# GD32A72_A74x register map
File version: 1.0
CPU: CM7 r2p1, little endian, MPU, FPU, DSP, 4 interrupt priority bits
Registers are 32-bit, read-write, reset 0x0 unless marked. A register's access mark holds for its fields unless they carry their own. Offsets are from the block's base; [hi:lo] are bit positions; {n}, {i} and the like mark numbered series; 'fields as' and 'values as' point back to an identical list.

## ENET_MAC
Base 0x4000A000
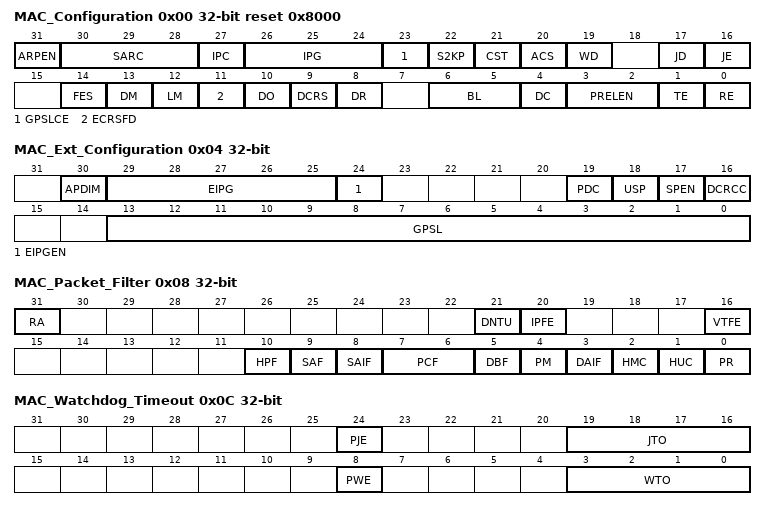
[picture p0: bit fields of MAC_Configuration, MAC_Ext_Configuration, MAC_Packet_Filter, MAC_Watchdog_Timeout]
0x00 MAC_Configuration reset 0x8000
  [31] ARPEN — ARP Offload Enable
  [30:28] SARC — Source Address Insertion Or Replacement Control
    0=SA_CTRL_IN (mti_sa_ctrl_i and ati_sa_ctrl_i input signals control the SA field generation); 2=MAC0_INS_SA (Contents of are inserted in the SA field); 3=MAC0_REP_SA (Contents of replace the SA field); 6=MAC1_INS_SA (Contents of are inserted in the SA field); 7=MAC1_REP_SA (Contents of replace the SA field)
  [27] IPC — Checksum Offload
    0=DISABLE (Disabled); 1=ENABLE (Enabled)
  [26:24] IPG — Inter-Packet Gap
    0=96-bit times IPG; 1=88-bit times IPG; 2=80-bit times IPG; 3=72-bit times IPG; 4=64-bit times IPG; 5=56-bit times IPG; 6=48-bit times IPG; 7=40-bit times IPG
  [23] GPSLCE — Giant Packet Size Limit Control Enable
    0=DISABLE (Disabled); 1=ENABLE (Enabled)
  [22] S2KP — IEEE 802.3 Support For 2K Packets
    0=DISABLE (Disabled); 1=ENABLE (Enabled)
  [21] CST — CRC Stripping For Type Packets
    0=DISABLE (Disabled); 1=ENABLE (Enabled)
  [20] ACS — Automatic Pad Or CRC Stripping
    0=DISABLE (Disabled); 1=ENABLE (Enabled)
  [19] WD — Watchdog Disable
    0=ENABLE (Enabled); 1=DISABLE (Disabled)
  [17] JD — Jabber Disable
    0=ENABLE (Enabled); 1=DISABLE (Disabled)
  [16] JE — Jumbo Packet Enable
    0=DISABLE (Disabled); 1=ENABLE (Enabled)
  [14] FES — Speed
    0=M_10_1000M (10 Mbit/s if PS = 1 and 1 Gbps if PS = 0); 1=M_100_2500M (100 Mbit/s if PS = 1 and 2.5 Gbps if PS = 0)
  [13] DM — Duplex Mode
    0=HDUPLX (Half-duplex mode); 1=FDUPLX (Full-duplex mode)
  [12] LM — Loopback Mode
    0=DISABLE (Disabled); 1=ENABLE (Enabled)
  [11] ECRSFD — Enable Carrier Sense In Full-Duplex Mode
    0=DISABLE (Disabled); 1=ENABLE (Enabled)
  [10] DO — Disable Receive Own
    0=ENABLE (Enabled); 1=DISABLE (Disabled)
  [9] DCRS — Disable Carrier Sense During Transmission
    0=ENABLE (Enabled); 1=DISABLE (Disabled)
  [8] DR — Disable Retry
    0=ENABLE (Enabled); 1=DISABLE (Disabled)
  [6:5] BL — Back-Off Limit
    0=MIN_N_10 (k = min(n,10)); 1=MIN_N_8 (k = min(n,8)); 2=MIN_N_4 (k = min(n,4)); 3=MIN_N_1 (k = min(n,1))
  [4] DC — Deferral Check
    0=DISABLE (Disabled); 1=ENABLE (Enabled)
  [3:2] PRELEN — Preamble Length for Transmit Packets
    0=M_7BYTES (7 bytes); 1=M_5BYTES (5 bytes); 2=M_3BYTES (3 bytes)
  [1] TE — Transmitter Enable
    0=DISABLE (Disabled); 1=ENABLE (Enabled)
  [0] RE — Receiver Enable
    0=DISABLE (Disabled); 1=ENABLE (Enabled)
0x04 MAC_Ext_Configuration — MAC Extended Configuration
  [30] APDIM — ARP Packet Drop if IP Address Mismatch
  [29:25] EIPG — Extended Inter-Packet Gap
  [24] EIPGEN — Extended Inter-Packet Gap Enable
    0=DISABLE (Disabled); 1=ENABLE (Enabled)
  [19] PDC — Packet Duplication Control
    0=DISABLE (Disabled); 1=ENABLE (Enabled)
  [18] USP — Unicast Slow Protocol Packet Detect
    0=DISABLE (Disabled); 1=ENABLE (Enabled)
  [17] SPEN — Slow Protocol Detection Enable
    0=DISABLE (Disabled); 1=ENABLE (Enabled)
  [16] DCRCC — Disable CRC Checking For Received Packets
    0=ENABLE (Enabled); 1=DISABLE (Disabled)
  [13:0] GPSL — Giant Packet Size Limit
0x08 MAC_Packet_Filter
  [31] RA — Receive All
    0=DISABLE (Receive All is disabled); 1=ENABLE (Receive All is enabled)
  [21] DNTU — Drop Non-TCP/UDP Over IP Packets
    0=FWD (Forwards); 1=DROP (Drops)
  [20] IPFE — Layer 3 and Layer 4 Filter Enable
    0=DISABLE (Disabled); 1=ENABLE (Enabled)
  [16] VTFE — VLAN Tag Filter Enable
    0=DISABLE (Disabled); 1=ENABLE (Enabled)
  [10] HPF — Hash Or Perfect Filter
    0=DISABLE (Disabled); 1=ENABLE (Enabled)
  [9] SAF — Source Address Filter Enable
    0=DISABLE (Disabled); 1=ENABLE (Enabled)
  [8] SAIF — SA Inverse Filtering
    0=DISABLE (Disabled); 1=ENABLE (Enabled)
  [7:6] PCF — Pass Control Packets
    0=FLTR_ALL (MAC filters all the control packets from reaching the application); 1=FW_XCPT_PAU (MAC forwards all the control packets, except pause packets, to the application even if they fail the address filter); 2=FW_ALL (MAC forwards all the control packets to the application even if they fail the address filter); 3=FW_PASS (MAC forwards all the control packets that pass the address filter)
  [5] DBF — Disable Broadcast Packets
    0=ENABLE (Enabled); 1=DISABLE (Disabled)
  [4] PM — Pass All Multicast
    0=DISABLE (Disabled); 1=ENABLE (Enabled)
  [3] DAIF — DA Inverse Filtering
    0=DISABLE (Disabled); 1=ENABLE (Enabled)
  [2] HMC — Hash Multicast
    0=DISABLE (Disabled); 1=ENABLE (Enabled)
  [1] HUC — Hash Unicast
    0=DISABLE (Disabled); 1=ENABLE (Enabled)
  [0] PR — Promiscuous Mode
    0=DISABLE (Disabled); 1=ENABLE (Enabled)
0x0C MAC_Watchdog_Timeout
  [24] PJE — Programmable Jabber Enable
  [19:16] JTO — Jabber Timeout
  [8] PWE — Programmable Watchdog Enable
    0=DISABLE (Disabled); 1=ENABLE (Enabled)
  [3:0] WTO — Watchdog Timeout
    {v}=M_{v+2}KBYTES ({v+2} KB) (v=0..13); 14=M_16383BYTES (16383 bytes)
0x10 MAC_Hash_Table_Reg0 — MAC Hash Table First 32 Bits
  [31:0] HT31T0
0x14 MAC_Hash_Table_Reg1 — MAC Hash Table Second 32 Bits
  [31:0] HT63T32
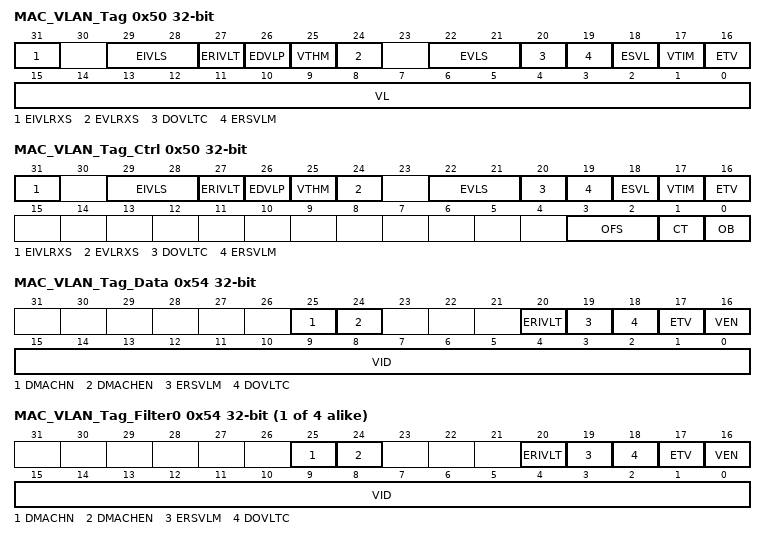
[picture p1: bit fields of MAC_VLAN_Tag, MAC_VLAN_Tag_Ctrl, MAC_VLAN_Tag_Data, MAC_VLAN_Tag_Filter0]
0x50 MAC_VLAN_Tag (MAC_VLAN view)
  [31] EIVLRXS — Enable Inner VLAN Tag In Receive Status
    0=DISABLE (Disabled); 1=ENABLE (Enabled)
  [29:28] EIVLS — Enable Inner VLAN Tag Stripping
    0=DONOT (Do not strip); 1=IFPASS (Strip if VLAN filter passes); 2=IFFAIL (Strip if VLAN filter fails); 3=ALWAYS (Always strip)
  [27] ERIVLT — Enable Inner VLAN Tag Comparison
    0=DISABLE (Disabled); 1=ENABLE (Enabled)
  [26] EDVLP — Enable Double VLAN Processing
    0=DISABLE (Disabled); 1=ENABLE (Enabled)
  [25] VTHM — VLAN Tag Hash Table Match
    0=DISABLE (Disabled); 1=ENABLE (Enabled)
  [24] EVLRXS — Enable VLAN Tag In Receive Status
    0=DISABLE (Disabled); 1=ENABLE (Enabled)
  [22:21] EVLS — Enable VLAN Tag Stripping
    values as EIVLS
  [20] DOVLTC — Disable VLAN Type Check
    0=ENABLE (Enabled); 1=DISABLE (Disabled)
  [19] ERSVLM — Enable Receive S-VLAN Match
    0=DISABLE (Disabled); 1=ENABLE (Enabled)
  [18] ESVL — Enable S-VLAN
    0=DISABLE (Disabled); 1=ENABLE (Enabled)
  [17] VTIM — VLAN Tag Inverse Match Enable
    0=DISABLE (Disabled); 1=ENABLE (Enabled)
  [16] ETV — Enable Tag For VLAN
    0=DISABLE (Disabled); 1=ENABLE (Enabled)
  [15:0] VL — VLAN Tag Identifier for Receive Packets
0x50 MAC_VLAN_Tag_Ctrl (MAC_VLAN view) — MAC VLAN Tag Control
  [31] EIVLRXS — Enable Inner VLAN Tag In Receive Status
    0=DISABLE (Disabled); 1=ENABLE (Enabled)
  [29:28] EIVLS — Enable Inner VLAN Tag Stripping
    values as MAC_VLAN_Tag.EIVLS
  [27] ERIVLT — Enable Inner VLAN Tag Comparison
    0=DISABLE (Disabled); 1=ENABLE (Enabled)
  [26] EDVLP — Enable Double VLAN Processing
    0=DISABLE (Disabled); 1=ENABLE (Enabled)
  [25] VTHM — VLAN Tag Hash Table Match
    0=DISABLE (Disabled); 1=ENABLE (Enabled)
  [24] EVLRXS — Enable VLAN Tag In Receive Status
    0=DISABLE (Disabled); 1=ENABLE (Enabled)
  [22:21] EVLS — Enable VLAN Tag Stripping
    values as MAC_VLAN_Tag.EIVLS
  [20] DOVLTC — Disable VLAN Type Check
    0=ENABLE (Enabled); 1=DISABLE (Disabled)
  [19] ERSVLM — Enable Receive S-VLAN Match
    0=DISABLE (Disabled); 1=ENABLE (Enabled)
  [18] ESVL — Enable S-VLAN
    0=DISABLE (Disabled); 1=ENABLE (Enabled)
  [17] VTIM — VLAN Tag Inverse Match Enable
    0=DISABLE (Disabled); 1=ENABLE (Enabled)
  [16] ETV — Enable Tag For VLAN
    0=DISABLE (Disabled); 1=ENABLE (Enabled)
  [3:2] OFS — Offset
  [1] CT — Command Type
    0=WRITE (Write operation); 1=READ (Read operation)
  [0] OB — Operation Busy
    0=DISABLE (Disabled); 1=ENABLE (Enabled)
0x54 MAC_VLAN_Tag_Data (MAC_VLAN_Tag view)
  [25] DMACHN — DMA Channel Number
  [24] DMACHEN — DMA Channel Number Enable
    0=DISABLE (Disabled); 1=ENABLE (Enabled)
  [20] ERIVLT — Enable Inner VLAN Tag
    0=DISABLE (Disabled); 1=ENABLE (Enabled)
  [19] ERSVLM — Enable S-VLAN Match
    0=DISABLE (Disabled); 1=ENABLE (Enabled)
  [18] DOVLTC — Disable VLAN Type Comparison
    0=ENABLE (Enabled); 1=DISABLE (Disabled)
  [17] ETV — VLAN Comparison
    0=M_16BIT (16-bit VLAN comparison); 1=M_12BIT (12-bit VLAN comparison)
  [16] VEN — VLAN Tag Enable
    0=DISABLE (Disabled); 1=ENABLE (Enabled)
  [15:0] VID — VLAN Tag ID
0x54 MAC_VLAN_Tag_Filter{i} (MAC_VLAN_Tag view) (i=0..3)
  fields as MAC_VLAN_Tag_Data
0x58 MAC_VLAN_Hash_Table
  [15:0] VLHT — VLAN Hash Table
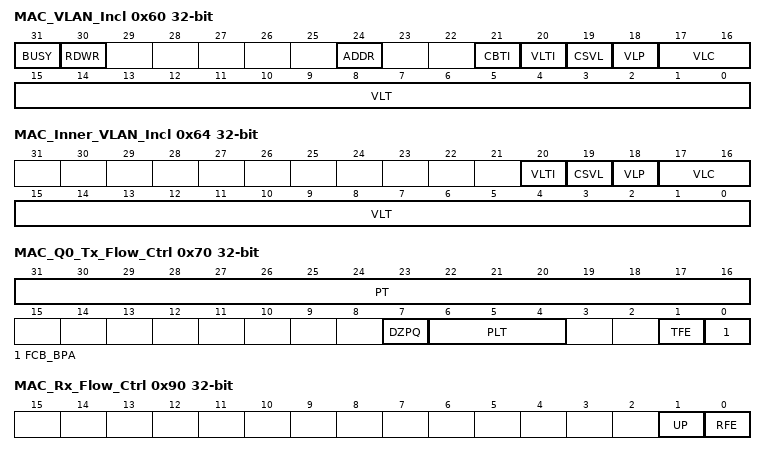
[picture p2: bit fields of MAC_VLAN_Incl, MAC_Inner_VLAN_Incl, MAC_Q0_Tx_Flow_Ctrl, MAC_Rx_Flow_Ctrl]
0x60 MAC_VLAN_Incl — MAC VLAN Inclusion Or Replacement
  [31] BUSY ro
    0=INACTIVE (Busy status not detected); 1=ACTIVE (Busy status detected)
  [30] RDWR — Read Write Control
    0=READ (Read operation of indirect access); 1=WRITE (Write operation of indirect access)
  [24] ADDR — Address
  [21] CBTI — Channel-Based Tag Insertion
    0=DISABLE (Disabled); 1=ENABLE (Enabled)
  [20] VLTI — VLAN Tag Input
    0=DISABLE (Disabled); 1=ENABLE (Enabled)
  [19] CSVL — C-VLAN Or S-VLAN
    0=CVLAN; 1=SVLAN
  [18] VLP — VLAN Priority Control
    0=DISABLE (Disabled); 1=ENABLE (Enabled)
  [17:16] VLC — VLAN Tag Control
    0=NONE (No VLAN tag deletion, insertion, or replacement); 1=DELETE (VLAN tag deletion); 2=INSERT (VLAN tag insertion); 3=REPLACE (VLAN tag replacement)
  [15:0] VLT — VLAN Tag For Transmit Packets
0x64 MAC_Inner_VLAN_Incl — Inner VLAN Tag Inclusion Or Replacement
  [20] VLTI — VLAN Tag Input
    0=DISABLE (Disabled); 1=ENABLE (Enabled)
  [19] CSVL — C-VLAN Or S-VLAN
    0=CVLAN (C-VLAN type (8100h)); 1=SVLAN (S-VLAN type (88A8h))
  [18] VLP — VLAN Priority Control
    0=DISABLE (Disabled); 1=ENABLE (Enabled)
  [17:16] VLC — VLAN Tag Control in Transmit Packets
    values as MAC_VLAN_Incl.VLC
  [15:0] VLT — VLAN Tag For Transmit Packets
0x70 MAC_Q0_Tx_Flow_Ctrl — MAC Q0 Tx Flow Control
  [31:16] PT — Pause Time
  [7] DZPQ — Disable Zero-Quanta Pause
    0=ENABLE (Enabled); 1=DISABLE (Disabled)
  [6:4] PLT — Pause Low Threshold
    0=PT4 (Pause time minus 4 slot times (PT is 4 slot times)); 1=PT28 (Pause time minus 28 slot times (PT is 28 slot times)); 2=PT36 (Pause time minus 36 slot times (PT is 36 slot times)); 3=PT144 (Pause time minus 144 slot times (PT is 144 slot times)); 4=PT256 (Pause time minus 256 slot times (PT is 256 slot times)); 5=PT512 (Pause time minus 512 slot times (PT is 512 slot times))
  [1] TFE — Transmit Flow Control Enable
    0=DISABLE (Disabled); 1=ENABLE (Enabled)
  [0] FCB_BPA — Flow Control Busy Or Backpressure Activate
    0=DISABLE (Flow control busy or backpressure activate is disabled); 1=ENABLE (Flow control busy or backpressure activate is enabled)
0x90 MAC_Rx_Flow_Ctrl — MAC Receive Flow Control
  [1] UP — Unicast Pause Packet Detect
    0=DISABLE (Disabled); 1=ENABLE (Enabled)
  [0] RFE — Receive Flow Control Enable
    0=DISABLE (Disabled); 1=ENABLE (Enabled)
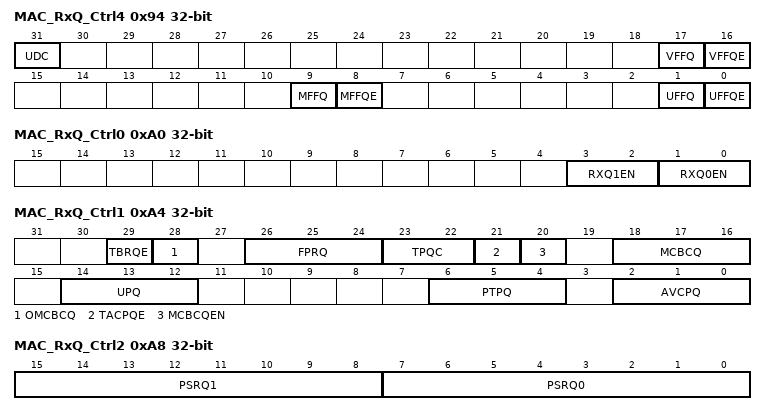
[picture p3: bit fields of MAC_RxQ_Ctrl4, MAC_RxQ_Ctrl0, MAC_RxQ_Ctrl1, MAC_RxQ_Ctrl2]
0x94 MAC_RxQ_Ctrl4 — MAC RxQ Control 4
  [31] UDC — Unicast Packet Duplication Control
  [17] VFFQ — VLAN Tag Filter Fail Packets Queue
  [16] VFFQE — VLAN Tag Filter Fail Packets Queuing Enable
    0=DISABLE (Disabled); 1=ENABLE (Enabled)
  [9] MFFQ — Multicast Address Filter Fail Packets Queue
  [8] MFFQE — Multicast Address Filter Fail Packets Queuing Enable
    0=DISABLE (Disabled); 1=ENABLE (Enabled)
  [1] UFFQ — Unicast Address Filter Fail Packets Queue
  [0] UFFQE — Unicast Address Filter Fail Packets Queuing Enable
    0=DISABLE (Disabled); 1=ENABLE (Enabled)
0xA0 MAC_RxQ_Ctrl0 — MAC RxQ Control 0
  [3:2] RXQ1EN — Receive Queue 1 Enable
    0=DISABLE (Queue not enabled); 1=EN_AV (Queue enabled for AV); 2=EN_DCB_GEN (Queue enabled for DCB/generic)
  [1:0] RXQ0EN — Receive Queue 0 Enable
    values as RXQ1EN
0xA4 MAC_RxQ_Ctrl1 — Receive Queue Control 1
  [29] TBRQE — Type Field Based Rx Queuing Enable
  [28] OMCBCQ — Over-riding MC-BC queue priority select
  [26:24] FPRQ — Frame Preemption Residue Queue
  [23:22] TPQC — Tagged PTP Over Ethernet Packets Queuing Control
  [21] TACPQE — Tagged AV Control Packets Queuing Enable
    0=DISABLE (Disabled); 1=ENABLE (Enabled)
  [20] MCBCQEN — Multicast And Broadcast Queue Enable
    0=DISABLE (Disabled); 1=ENABLE (Enabled)
  [18:16] MCBCQ — Multicast And Broadcast Queue
    {v}=QUEUE{v} (Receive queue {v}) (v=0..7)
  [14:12] UPQ — Untagged Packet Queue
    {v}=QUEUE{v} (Receive queue {v}) (v=0..7)
  [6:4] PTPQ — PTP Packets Queue
    {v}=QUEUE{v} (Receive queue {v}) (v=0..7)
  [2:0] AVCPQ — AV Untagged Control Packets Queue
    {v}=QUEUE{v} (Receive queue {v}) (v=0..7)
0xA8 MAC_RxQ_Ctrl2 — MAC RxQ Control 2
  [15:8] PSRQ1 — Priorities Selected In Receive Queue 1
  [7:0] PSRQ0 — Priorities Selected In Receive Queue 0
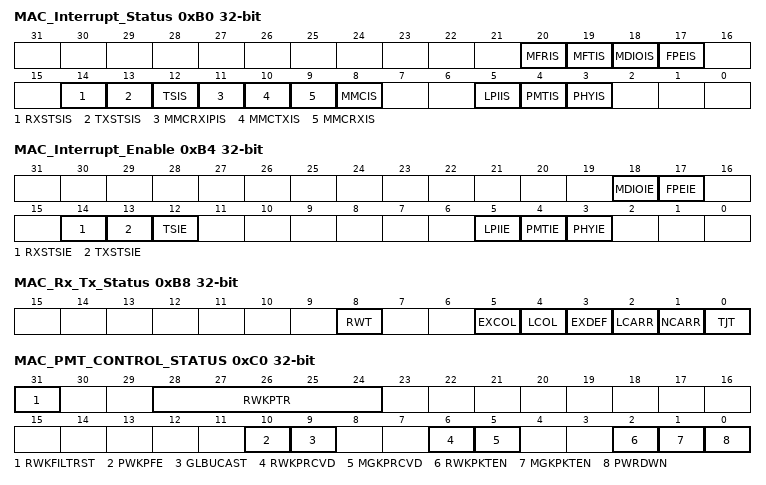
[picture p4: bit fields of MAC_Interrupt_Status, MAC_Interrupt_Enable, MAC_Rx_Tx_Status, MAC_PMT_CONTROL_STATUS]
0xB0 MAC_Interrupt_Status ro
  [20] MFRIS — MMC FPE Receive Interrupt Status
    0=INACTIVE; 1=ACTIVE
  [19] MFTIS — MMC FPE Transmit Interrupt Status
    0=INACTIVE; 1=ACTIVE
  [18] MDIOIS — MDIO Interrupt Status
    0=INACTIVE; 1=ACTIVE
  [17] FPEIS — Frame Preemption Interrupt Status
    0=INACTIVE; 1=ACTIVE (Ative)
  [14] RXSTSIS — Receive Status Interrupt
    0=INACTIVE; 1=ACTIVE
  [13] TXSTSIS — Transmit Status Interrupt
    0=INACTIVE; 1=ACTIVE
  [12] TSIS — Timestamp Interrupt Status
    0=INACTIVE; 1=ACTIVE
  [11] MMCRXIPIS — MMC Receive Checksum Offload Interrupt Status
  [10] MMCTXIS — MMC Transmit Interrupt Status
    0=INACTIVE; 1=ACTIVE
  [9] MMCRXIS — MMC Receive Interrupt Status
    0=INACTIVE; 1=ACTIVE
  [8] MMCIS — MMC Interrupt Status
    0=INACTIVE; 1=ACTIVE
  [5] LPIIS — LPI Interrupt Status
  [4] PMTIS — PMT Interrupt Status
  [3] PHYIS — PHY Interrupt
    0=INACTIVE (Not detected); 1=ACTIVE (Detected)
0xB4 MAC_Interrupt_Enable
  [18] MDIOIE — MDIO Interrupt Enable
    0=DISABLE (Disabled); 1=ENABLE (Enabled)
  [17] FPEIE — Frame Preemption Interrupt Enable
    0=DISABLE (Disabled); 1=ENABLE (Enabled)
  [14] RXSTSIE — Receive Status Interrupt Enable
    0=DISABLE (Disabled); 1=ENABLE (Enabled)
  [13] TXSTSIE — Transmit Status Interrupt Enable
    0=DISABLE (Disabled); 1=ENABLE (Enabled)
  [12] TSIE — Timestamp Interrupt Enable
    0=DISABLE (Disabled); 1=ENABLE (Enabled)
  [5] LPIIE — LPI Interrupt Enable
  [4] PMTIE — PMT Interrupt Enable
  [3] PHYIE — PHY Interrupt Enable
    0=DISABLE (Disabled); 1=ENABLE (Enabled)
0xB8 MAC_Rx_Tx_Status ro — MAC Rx Transmit Status
  [8] RWT — Receive Watchdog Timeout
    0=INACTIVE (No receive watchdog timed out); 1=ACTIVE (Receive watchdog timed out)
  [5] EXCOL — Excessive Collisions
    0=INACTIVE (No collision); 1=ACTIVE (Excessive collision is sensed)
  [4] LCOL — Late Collision
    0=INACTIVE (No collision); 1=ACTIVE (Late collision is sensed)
  [3] EXDEF — Excessive Deferral
    0=INACTIVE (No excessive deferral); 1=ACTIVE (Excessive deferral)
  [2] LCARR — Loss of Carrier
    0=INACTIVE (Carrier is present); 1=ACTIVE (Loss of carrier)
  [1] NCARR — No Carrier
    0=INACTIVE (Present); 1=ACTIVE (Absent)
  [0] TJT — Transmit Jabber Timeout
    0=INACTIVE (No transmit jabber timeout occurred); 1=ACTIVE (Transmit jabber timeout occurred)
0xC0 MAC_PMT_CONTROL_STATUS access per field — MAC PMT control and status register
  [31] RWKFILTRST rw — Remote Wake-Up Packet Filter Register Pointer Reset
  [28:24] RWKPTR ro — Remote Wake-up FIFO Pointer
  [10] PWKPFE rw — Remote Wake-up Packet Forwarding Enable
  [9] GLBUCAST rw — Global unicast bit
  [6] RWKPRCVD ro — Remote Wake-Up Packet Received
  [5] MGKPRCVD ro — Magic Packet Received
  [2] RWKPKTEN rw — Wakeup frame enable bit
  [1] MGKPKTEN rw — Magic Packet enable bit
  [0] PWRDWN rw — Power down bit
0xC4 MAC_RWK_Packet_Filter — MAC remote wakeup packet filter register
  [31:0] WKUPFRMFTR — RWK Packet Filter
0xC4 RWK_Filter0123_Byte_Mask (MAC_RWK_Packet_Filter view) — MAC remote wakeup packet filter0123 byte mask register
  [30:0] Filter0_Byte_Mask — Filter0 32-bit Mask
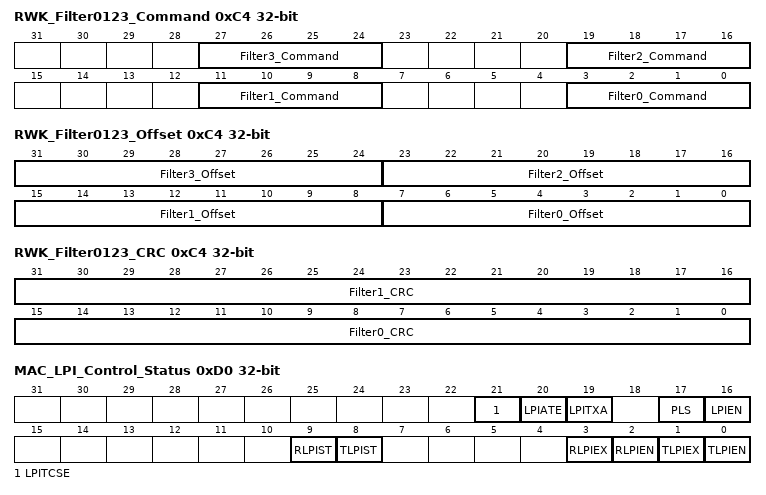
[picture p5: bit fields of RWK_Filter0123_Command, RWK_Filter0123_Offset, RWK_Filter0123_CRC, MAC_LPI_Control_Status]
0xC4 RWK_Filter0123_Command (MAC_RWK_Packet_Filter view) — MAC remote wakeup packet filter0123 command register
  [8n+3:8n] Filter{n}_Command (n=0..3)
0xC4 RWK_Filter0123_Offset (MAC_RWK_Packet_Filter view) — MAC remote wakeup packet filter0123 offset register
  [8n+7:8n] Filter{n}_Offset (n=0..3)
0xC4 RWK_Filter0123_CRC (MAC_RWK_Packet_Filter view) — MAC remote wakeup packet filter#i crc register
  [31:16] Filter1_CRC — Filter1 CRC-16
  [15:0] Filter0_CRC — Filter0 CRC-16
0xD0 MAC_LPI_Control_Status access per field — MAC LPI control and status register
  [21] LPITCSE rw — LPI Tx Clock Stop Enable
  [20] LPIATE rw — LPI Timer Enable
  [19] LPITXA rw — LPI Tx Automate
  [17] PLS rw — PHY Link Status
  [16] LPIEN rw — LPI Enable
  [9] RLPIST ro — Receive LPI State
  [8] TLPIST ro — Transmit LPI State
  [3] RLPIEX ro — Receive LPI Exit
  [2] RLPIEN ro — Receive LPI Entry
  [1] TLPIEX ro — Transmit LPI Exit
  [0] TLPIEN ro — Transmit LPI Entry
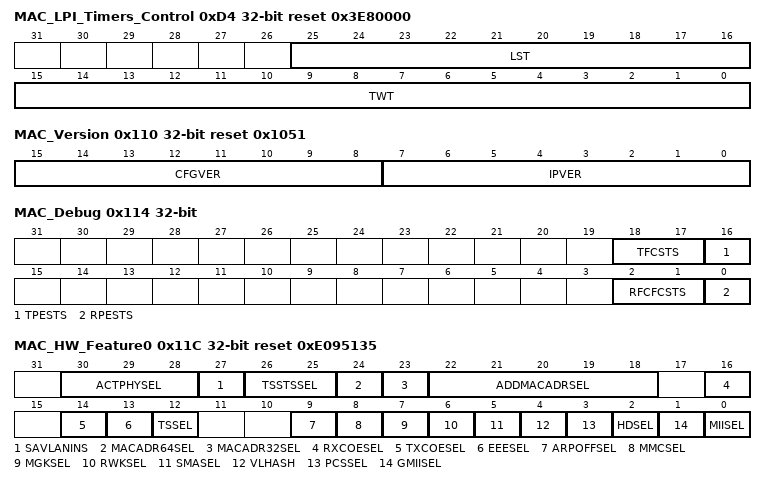
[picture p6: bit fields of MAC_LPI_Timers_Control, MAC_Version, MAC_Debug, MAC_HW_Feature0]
0xD4 MAC_LPI_Timers_Control reset 0x3E80000
  [25:16] LST — LPI LS Timer
  [15:0] TWT — LPI TW Timer
0xD8 MAC_LPI_Entry_Timer
  [19:3] LPIET — LPI Entry Timer
0xDC MAC_1US_Tic_Counter — MAC 1 microsecond tic counter register
  [11:0] TIC_1US_CNTR — 1US TIC Counter
0x110 MAC_Version ro reset 0x1051
  [15:8] CFGVER — IP Configuration Version
  [7:0] IPVER — IP Version
0x114 MAC_Debug ro
  [18:17] TFCSTS — MAC Transmit Packet Controller Status
    0=IDLE (Idle state); 1=WAITING (Waiting for one of these: status of the previous packet or IPG, or for the back-off period to be over); 2=GEN_TX_PAU (Generating and transmitting a pause control packet (in Full-Duplex mode)); 3=TRNSFR (Transferring input packet for transmission)
  [16] TPESTS — MAC GMII Or MII Transmit Protocol Engine Status
    0=INACTIVE (Not detected); 1=ACTIVE (Detected)
  [2:1] RFCFCSTS — MAC Receive Packet Controller FIFO Status
    0=INACTIVE; 1=ACTIVE
  [0] RPESTS — Receive Protocol Engine Status
    0=INACTIVE (Not detected); 1=ACTIVE (Detected)
0x11C MAC_HW_Feature0 ro reset 0xE095135 — MAC Hardware Feature 0
  [30:28] ACTPHYSEL — Active PHY Feature
    0=GMII_MII (GMII or MII); 1=RGMII; 2=SGMII; 3=TBI; 4=RMII; 5=RTBI; 6=SMII; 7=REVMIII
  [27] SAVLANINS — SA or VLAN Insertion Feature
    0=INACTIVE (Not selected); 1=ACTIVE (Selected)
  [26:25] TSSTSSEL — Timestamp System Time Source Feature
    0=INTRNL (Internal); 1=EXTRNL (External); 2=BOTH (Both internal and external)
  [24] MACADR64SEL — MAC Addresses 64-127
    0=INACTIVE (Not selected); 1=ACTIVE (Selected)
  [23] MACADR32SEL — MAC Addresses 32-63
    0=INACTIVE (Not selected); 1=ACTIVE (Selected)
  [22:18] ADDMACADRSEL — MAC Addresses 1-31
    0=INACTIVE (Not selected); 1=ACTIVE (Selected)
  [16] RXCOESEL — Receive Checksum Offload Feature
    0=INACTIVE (Not selected); 1=ACTIVE (Selected)
  [14] TXCOESEL — Transmit Checksum Offload Feature
    0=INACTIVE (Not selected); 1=ACTIVE (Selected)
  [13] EEESEL — Energy Efficient Ethernet (EEE) Feature
    0=INACTIVE (Not selected); 1=ACTIVE (Selected)
  [12] TSSEL — IEEE 1588-2008 Timestamp Feature
    0=INACTIVE (Not selected); 1=ACTIVE (Selected)
  [9] ARPOFFSEL — ARP Offload Feature
    0=INACTIVE (Not selected); 1=ACTIVE (Selected)
  [8] MMCSEL — MAC Management Counters (MMC) Feature
    0=INACTIVE (Not selected); 1=ACTIVE (Selected)
  [7] MGKSEL — PMT Magic Packet Feature
    0=INACTIVE (Not selected); 1=ACTIVE (Selected)
  [6] RWKSEL — PMT Remote Wake-Up Packet Feature
    0=INACTIVE (Not selected); 1=ACTIVE (Selected)
  [5] SMASEL — SMA (MDIO) Interface Feature
    0=INACTIVE (Not selected); 1=ACTIVE (Selected)
  [4] VLHASH — VLAN Hash Filter Feature
    0=INACTIVE (Not selected); 1=ACTIVE (Selected)
  [3] PCSSEL — PCS Select
    0=INACTIVE (No); 1=ACTIVE (Yes)
  [2] HDSEL — Half-Duplex Support Feature
    0=INACTIVE (Unavailable); 1=ACTIVE (Available)
  [1] GMIISEL — 1000 Mbit/s Support Feature
    0=INACTIVE (Unavailable); 1=ACTIVE (Available)
  [0] MIISEL — 10 or 100 Mbit/s Support Feature
    0=INACTIVE (Unavailable); 1=ACTIVE (Available)
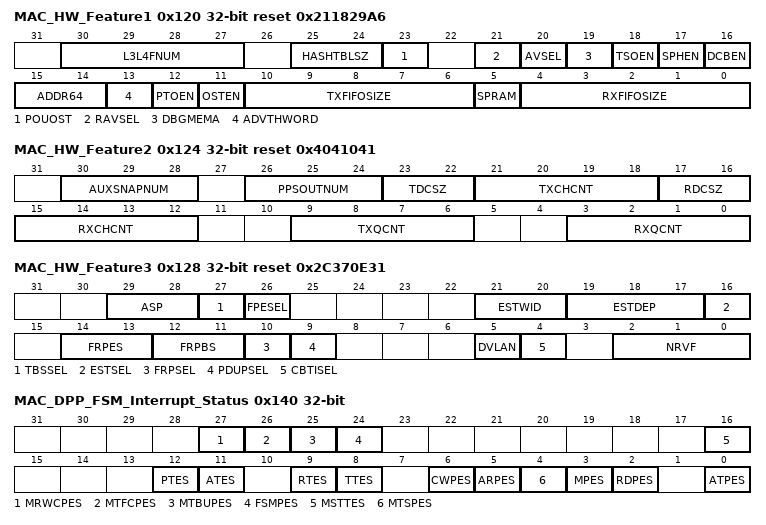
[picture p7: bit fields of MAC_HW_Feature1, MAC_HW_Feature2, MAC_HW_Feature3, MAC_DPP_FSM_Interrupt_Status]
0x120 MAC_HW_Feature1 ro reset 0x211829A6 — MAC Hardware Feature 1
  [30:27] L3L4FNUM — L3 Or L4 Filter Number
    0=NOFILT (No filters (0)); {v}=M_{v}FILT ({v}) (v=1..8)
  [25:24] HASHTBLSZ — Hash Table Size
    0=NO_HT (No hash table); 1=M_64 (64); 2=M_128 (128); 3=M_256 (256)
  [23] POUOST — One Step For PTP Over UDP/IP Feature
    0=INACTIVE (Not selected); 1=ACTIVE (Selected)
  [21] RAVSEL — Receive Side-Only AV Feature
    0=INACTIVE (Not selected); 1=ACTIVE (Selected)
  [20] AVSEL — AV Feature
    0=INACTIVE (Not selected); 1=ACTIVE (Selected)
  [19] DBGMEMA — DMA Debug Registers Enable Feature
    0=INACTIVE (Not selected); 1=ACTIVE (Selected)
  [18] TSOEN — TCP Segmentation Offload Enable Feature
    0=INACTIVE (Not selected); 1=ACTIVE (Selected)
  [17] SPHEN — Split Header Enable Feature
    0=INACTIVE (Not selected); 1=ACTIVE (Selected)
  [16] DCBEN — DCB Enable Feature
    0=INACTIVE (Not selected); 1=ACTIVE (Selected)
  [15:14] ADDR64 — Address Width Feature
    0=M_32 (32); 1=M_40 (40); 2=M_48 (48)
  [13] ADVTHWORD — IEEE 1588 High-Word Feature
    0=INACTIVE (Not selected); 1=ACTIVE (Selected)
  [12] PTOEN — PTP Offload Enable Feature
    0=INACTIVE (Not selected); 1=ACTIVE (Selected)
  [11] OSTEN — One-Step Timestamping Enable Feature
    0=INACTIVE (Not selected); 1=ACTIVE (Selected)
  [10:6] TXFIFOSIZE — MTL Transmit FIFO Size Feature
    0=M_128B (128 bytes); 1=M_256B (256 bytes); 2=M_512B (512 bytes); 3=M_1024B (1024 bytes); 4=M_2048B (2048 bytes); 5=M_4096B (4096 bytes); 6=M_8192B (8192 bytes); 7=M_16384B (16384 bytes); 8=M_32KB (32 KB); 9=M_64KB (64 KB); 10=M_128KB (128 KB)
  [5] SPRAM — Single Port RAM Feature
    0=INACTIVE (Not selected); 1=ACTIVE (Selected)
  [4:0] RXFIFOSIZE — MTL Receive FIFO Size Feature
    0=M_128B (128 bytes); 1=M_256B (256 bytes); 2=M_512B (512 bytes); 3=M_1024B (1024 bytes); 4=M_2048B (2048 bytes); 5=M_4096B (4096 bytes); 6=M_8192B (8192 bytes); 7=M_16384B (16384 bytes); 8=M_32KB (32 KB); 9=M_64KB (64 KB); 10=M_128KB (128 KB); 11=M_256KB (256 KB)
0x124 MAC_HW_Feature2 ro reset 0x4041041 — MAC Hardware Feature 2
  [30:28] AUXSNAPNUM — Number Of Auxiliary Snapshot Inputs
    0=NO_AUXI (No auxiliary input (0)); {v}=M_{v}_AUXI ({v}) (v=1..4)
  [26:24] PPSOUTNUM — Number Of PPS Outputs
    0=NO_PPSO (No PPS output (0)); {v}=M_{v}_PPSO ({v}) (v=1..4)
  [23:22] TDCSZ — Tx DMA Descriptor Cache Size in terms of 16-bytes descriptors
  [21:18] TXCHCNT — Number Of DMA Transmit Channels
    {v}=M_{v+1}TXCH ({v+1}) (v=0..7)
  [17:16] RDCSZ — Rx DMA Descriptor Cache Size in terms of 16-bytes descriptors
  [15:12] RXCHCNT — Number Of DMA Receive Channels
    {v}=M_{v+1}RXCH ({v+1}) (v=0..7)
  [9:6] TXQCNT — Number Of MTL Transmit Queues
    {v}=M_{v+1}TXQ ({v+1}) (v=0..7)
  [3:0] RXQCNT — Number Of MTL Receive Queues
    {v}=M_{v+1}RXQ ({v+1}) (v=0..7)
0x128 MAC_HW_Feature3 ro reset 0x2C370E31 — MAC Hardware Feature 3
  [29:28] ASP — Automotive Safety Package
    0=NONE (No safety features selected); 1=ECC_ONLY (Only "ECC protection for external memory" feature is selected); 2=AS_NPPE (All the safety features are selected without the "parity port enable for external interface" feature); 3=AS_PPE (All the safety features are selected with the "parity port enable for external interface" feature)
  [27] TBSSEL — Time-Based Scheduling Feature
    0=INACTIVE (Selected); 1=ACTIVE (Selected)
  [26] FPESEL — Frame Preemption Feature
    0=INACTIVE (Not selected); 1=ACTIVE (Selected)
  [21:20] ESTWID — Estimated Time Interval Width
    0=NOWIDTH (Width not configured); 1=WIDTH16 (16 bits); 2=WIDTH20 (20 bits); 3=WIDTH24 (24 bits)
  [19:17] ESTDEP — Depth Of Gate Control List
    0=NODEPTH (No depth configured); 1=DEPTH64 (64 bytes); 2=DEPTH128 (128 bytes); 3=DEPTH256 (256 bytes); 4=DEPTH512 (512 bytes); 5=DEPTH1024 (1024 bytes)
  [16] ESTSEL — Enhancements To Scheduling Traffic Feature
    0=INACTIVE (Not selected); 1=ACTIVE (Selected)
  [14:13] FRPES — Flexible Receive Parser Table Entry Size
    0=M_64ENTR (64); 1=M_128ENTR (128); 2=M_256ENTR (256)
  [12:11] FRPBS — Flexible Receive Parser Buffer Size
    0=M_64BYTES (64); 1=M_128BYTES (128); 2=M_256BYTES (256)
  [10] FRPSEL — Flexible Receive Parser Feature
    0=INACTIVE (Not selected); 1=ACTIVE (Selected)
  [9] PDUPSEL — Broadcast/Multicast Packet Duplication Feature
    0=INACTIVE (Not selected); 1=ACTIVE (Selected)
  [5] DVLAN — Double VLAN Tag Processing Feature
    0=INACTIVE (Not selected); 1=ACTIVE (Selected)
  [4] CBTISEL — Queue/Channel Based VLAN Tag Insertion On Transmit Feature
    0=INACTIVE (Not selected); 1=ACTIVE (Selected)
  [2:0] NRVF — Number Of Extended VLAN Tag Filters Indicates the number of selected extended VLAN tag filters.
    0=NO_ERVLAN (No filters (0)); 1=M_4_ERVLAN (4); 2=M_8_ERVLAN (8); 3=M_16_ERVLAN (16); 4=M_24_ERVLAN (24); 5=M_32_ERVLAN (32)
0x140 MAC_DPP_FSM_Interrupt_Status ro
  [27] MRWCPES — MTL RWC data path Parity Checker Error Status
  [26] MTFCPES — MAC TFC data path Parity Checker Error Status
  [25] MTBUPES — MAC TBU data path Parity Checker Error Status
  [24] FSMPES — FSM State Parity Error Status
    0=INACTIVE (Not detected); 1=ACTIVE (Detected)
  [16] MSTTES — Master Read Or Write Timeout Error Status
    0=INACTIVE (Not detected); 1=ACTIVE (Detected)
  [12] PTES — PTP FSM Timeout Error Status
    0=INACTIVE (Not detected); 1=ACTIVE (Detected)
  [11] ATES — APP FSM Timeout Error Status
    0=INACTIVE (Not detected); 1=ACTIVE (Detected)
  [9] RTES — Receive FSM Timeout Error Status
    0=INACTIVE (Not detected); 1=ACTIVE (Detected)
  [8] TTES — Transmit FSM Timeout Error Status
    0=INACTIVE (Not detected); 1=ACTIVE (Detected)
  [6] CWPES — CSR Write data path Parity Checker Error Status
  [5] ARPES — Application Receive Interface Data Path Parity Error Status
    0=INACTIVE (Not detected); 1=ACTIVE (Detected)
  [4] MTSPES — MTL Transmit Status Data Path Parity Checker Error Status
    0=INACTIVE (Not detected); 1=ACTIVE (Detected)
  [3] MPES — MTL Data Path Parity Checker Error Status
    0=INACTIVE (Not detected); 1=ACTIVE (Detected)
  [2] RDPES — Read Descriptor Parity Checker Error Status
    0=INACTIVE (Not detected); 1=ACTIVE (Detected)
  [0] ATPES — Application Transmit Interface Parity Checker Error Status
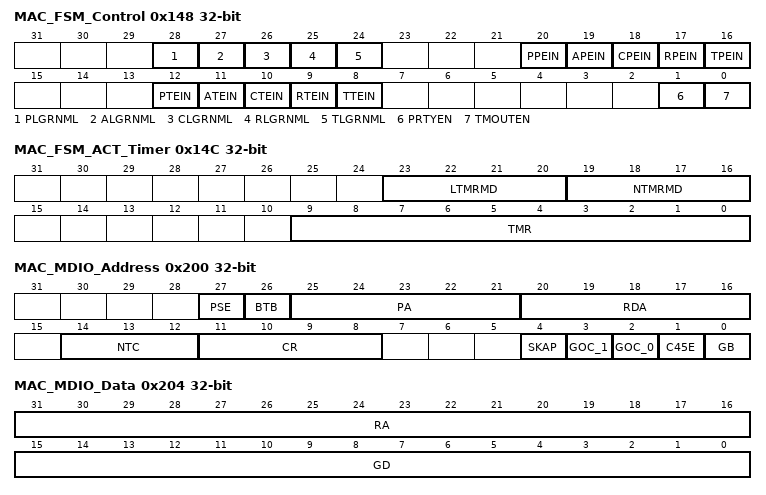
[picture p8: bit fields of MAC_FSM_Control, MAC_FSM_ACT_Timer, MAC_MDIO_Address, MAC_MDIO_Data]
0x148 MAC_FSM_Control
  [28] PLGRNML — PTP Large Or Normal Mode Select
    0=DISABLE (Normal mode); 1=ENABLE (Large mode)
  [27] ALGRNML — APP Large Or Normal Mode Select
    0=DISABLE (Normal mode); 1=ENABLE (Large mode)
  [26] CLGRNML — CSR Large/Normal Mode Select
    0=DISABLE (Normal mode); 1=ENABLE (Large mode)
  [25] RLGRNML — Receive Large Or Normal Mode Select
    0=DISABLE (Normal mode); 1=ENABLE (Large mode)
  [24] TLGRNML — Transmit Large Or Normal Mode Select
    0=DISABLE (Normal mode); 1=ENABLE (Large mode)
  [20] PPEIN — PTP FSM Parity Error Injection
    0=DISABLE (Disabled); 1=ENABLE (Enabled)
  [19] APEIN — APP FSM Parity Error Injection
    0=DISABLE (Disabled); 1=ENABLE (Enabled)
  [18] CPEIN — CSR FSM One Hot Protection Error Injection
    0=DISABLE (Disabled); 1=ENABLE (Enabled)
  [17] RPEIN — Receive FSM Parity Error Injection
    0=DISABLE (Disabled); 1=ENABLE (Enabled)
  [16] TPEIN — Transmit FSM Parity Error Injection
    0=DISABLE (Disabled); 1=ENABLE (Enabled)
  [12] PTEIN — PTP FSM Timeout Error Injection
    0=DISABLE (Disabled); 1=ENABLE (Enabled)
  [11] ATEIN — APP FSM Timeout Error Injection
    0=DISABLE (Disabled); 1=ENABLE (Enabled)
  [10] CTEIN — CSR FSM Timeout Error Injection
    0=DISABLE (Disabled); 1=ENABLE (Enabled)
  [9] RTEIN — Receive FSM Timeout Error Injection
    0=DISABLE (Disabled); 1=ENABLE (Enabled)
  [8] TTEIN — Transmit FSM Timeout Error Injection
    0=DISABLE (Disabled); 1=ENABLE (Enabled)
  [1] PRTYEN — Parity Enable
    0=DISABLE (Disabled); 1=ENABLE (Enabled)
  [0] TMOUTEN — Time Out Enable
    0=DISABLE (Disabled); 1=ENABLE (Enabled)
0x14C MAC_FSM_ACT_Timer
  [23:20] LTMRMD — Large Mode Timeout Value
    0=DISABLE (Timer disabled); 1=M_1MICRO_SEC (1 us); 2=M_4MILLI_SEC (1.024 ms (~4 ms)); 3=M_16MILLI_SEC (16.384 ms (~16 ms)); 4=M_64MILLI_SEC (65.536 ms (~64 ms)); 5=M_256MILLI_SEC (262.144 ms (~256 ms)); 6=M_1SEC (1.048 sec (~1 sec)); 7=M_4SEC (4.194 sec (~4sec)); 8=M_16SEC (16.777 sec (~16 sec)); 9=M_32SEC (33.554 sec (~32 sec)); 10=M_64SEC (67.108 sec (~64 sec))
  [19:16] NTMRMD — Normal Mode Timeout Value
    0=DISABLE (Timer disabled); 1=M_1MICRO_SEC (1 us); 2=M_4MILLI_SEC (1.024 ms (~4 ms)); 3=M_16MILLI_SEC (16.384 ms (~16 ms)); 4=M_64MILLI_SEC (65.536 ms (~64 ms)); 5=M_256MILLI_SEC (262.144 ms (~256 ms)); 6=M_1SEC (1.048 sec (~1 sec)); 7=M_4SEC (4.194 sec (~4 sec)); 8=M_16SEC (16.777 sec (~16 sec)); 9=M_32SEC (33.554 sec (~32 sec)); 10=M_64SEC (67.108 sec (~64 sec))
  [9:0] TMR — CSR Clocks For 1 us Tic
0x200 MAC_MDIO_Address
  [27] PSE — Preamble Suppression Enable
    0=DISABLE (Disabled); 1=ENABLE (Enabled)
  [26] BTB — Back-To-Back Transactions
    0=DISABLE (Disabled); 1=ENABLE (Enabled)
  [25:21] PA — Physical Layer Address
  [20:16] RDA — Register Or Device Address
  [14:12] NTC — Number Of Trailing Clocks
  [11:8] CR — CSR Clock Range
  [4] SKAP — Skip Address Packet
    0=DISABLE (Disabled); 1=ENABLE (Enabled)
  [3] GOC_1 — GMII Operation Command 1
    0=DISABLE (Disabled); 1=ENABLE (Enabled)
  [2] GOC_0 — GMII Operation Command 0
    0=DISABLE (Disabled); 1=ENABLE (Enabled)
  [1] C45E — Clause 45 PHY Enable
    0=DISABLE (Disabled); 1=ENABLE (Enabled)
  [0] GB — GMII Busy
    0=DISABLE (Disabled); 1=ENABLE (Enabled)
0x204 MAC_MDIO_Data
  [31:16] RA — Register Address
  [15:0] GD — GMII Data
0x210 MAC_ARP_Address — ARP address register
  [31:0] ARPPA — ARP Protocol Address
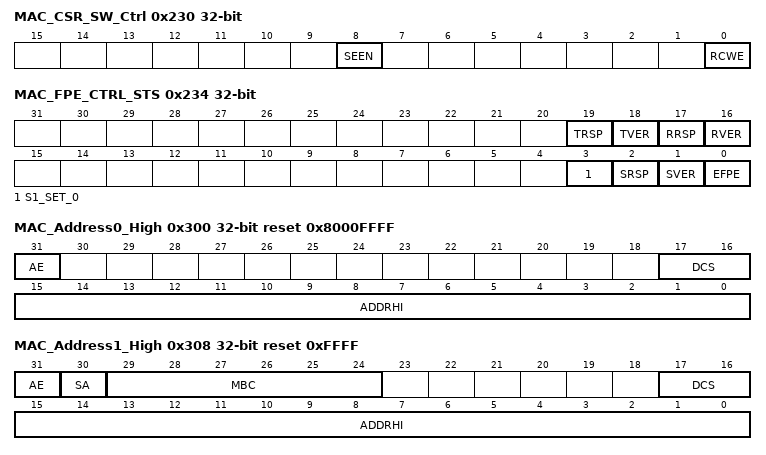
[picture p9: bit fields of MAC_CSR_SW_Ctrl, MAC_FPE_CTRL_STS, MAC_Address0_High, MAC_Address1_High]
0x230 MAC_CSR_SW_Ctrl — MAC CSR Software Control
  [8] SEEN — Slave Error Response Enable
    0=DISABLE (Disabled); 1=ENABLE (Enabled)
  [0] RCWE — Enable Register Write 1 To Clear (W1C)
    0=DISABLE (Disabled); 1=ENABLE (Enabled)
0x234 MAC_FPE_CTRL_STS — MAC FPE Control STS
  [19] TRSP — Transmitted Respond Frame
    0=INACTIVE (Not transmitted); 1=ACTIVE (Transmitted)
  [18] TVER — Transmitted Verify Frame
    0=INACTIVE (Not transmitted); 1=ACTIVE (Transmitted)
  [17] RRSP — Received Respond Frame
    0=INACTIVE (Not received); 1=ACTIVE (Received)
  [16] RVER — Received Verify Frame
    0=INACTIVE (Not received); 1=ACTIVE (Received)
  [3] S1_SET_0
  [2] SRSP — Send Respond mPacket
    0=DISABLE (Disabled); 1=ENABLE (Enabled)
  [1] SVER — Send Verify mPacket
    0=DISABLE (Disabled); 1=ENABLE (Enabled)
  [0] EFPE — Enable Transmit Frame Preemption
    0=DISABLE (Disabled); 1=ENABLE (Enabled)
0x240 MAC_Presn_Time_ns ro — MAC Presentation Time
  [31:0] MPTN — MAC 1722 Presentation Time (In Nanoseconds)
0x244 MAC_Presn_Time_Updt — MAC Presentation Time Update
  [31:0] MPTU — MAC 1722 Presentation Time Update
0x300 MAC_Address0_High reset 0x8000FFFF
  [31] AE ro — Address Enable
    0=DISABLE (Disabled and invalid (the field's value must always be 1)); 1=ENABLE (Enabled)
  [17:16] DCS — DMA Channel Select
  [15:0] ADDRHI — MAC Address 0 [47:32]
0x304 MAC_Address0_Low reset 0xFFFFFFFF
  [31:0] ADDRLO — MAC Address 0 [31:0]
0x308 MAC_Address1_High reset 0xFFFF
  [31] AE — Address Enable
    0=DISABLE (Ignored); 1=ENABLE (Enabled)
  [30] SA — Source Address
    0=DA (Destination address); 1=SA (Source address)
  [29:24] MBC — Mask Byte Control
  [17:16] DCS — DMA Channel Select
  [15:0] ADDRHI — MAC Address 1 [47:32]
0x30C MAC_Address1_Low reset 0xFFFFFFFF
  [31:0] ADDRLO — MAC Address 1 [31:0]
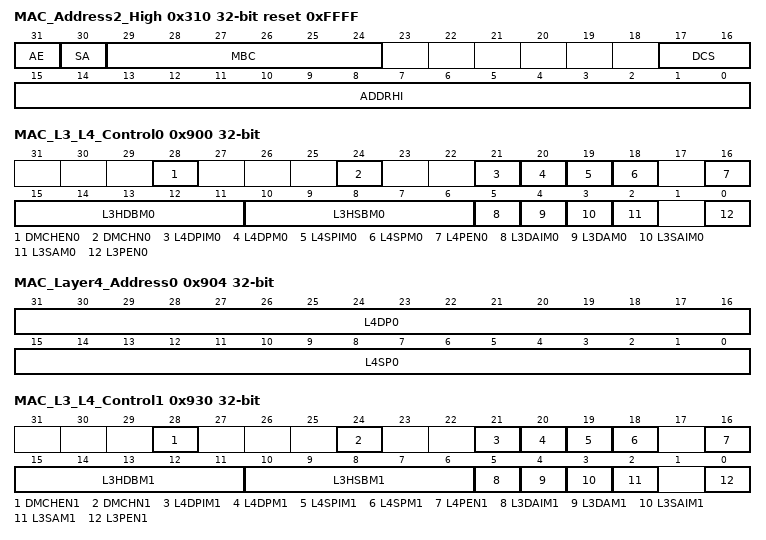
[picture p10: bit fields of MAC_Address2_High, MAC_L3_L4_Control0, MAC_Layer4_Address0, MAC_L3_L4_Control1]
0x310 MAC_Address2_High reset 0xFFFF
  fields as MAC_Address1_High
0x314 MAC_Address2_Low reset 0xFFFFFFFF
  [31:0] ADDRLO — MAC Address 1 [31:0]
0x900 MAC_L3_L4_Control0 — MAC Layer 3 Layer 4 Control 0
  [28] DMCHEN0 — DMA Channel Select Enable
    0=DISABLE (Disabled); 1=ENABLE (Enabled)
  [24] DMCHN0 — DMA Channel Number
  [21] L4DPIM0 — Layer 4 Destination Port Inverse Match Enable
    0=DISABLE (Disabled); 1=ENABLE (Enabled)
  [20] L4DPM0 — Layer 4 Destination Port Match Enable
    0=DISABLE (Disabled); 1=ENABLE (Enabled)
  [19] L4SPIM0 — Layer 4 Source Port Inverse Match Enable
    0=DISABLE (Disabled); 1=ENABLE (Enabled)
  [18] L4SPM0 — Layer 4 Source Port Match Enable
    0=DISABLE (Disabled); 1=ENABLE (Enabled)
  [16] L4PEN0 — Layer 4 Protocol Enable
    0=DISABLE (Disabled); 1=ENABLE (Enabled)
  [15:11] L3HDBM0 — Layer 3 IP DA Higher Bits Match
  [10:6] L3HSBM0 — Layer 3 IP SA Higher Bits Match
  [5] L3DAIM0 — Layer 3 IP DA Inverse Match Enable
    0=DISABLE (Disabled); 1=ENABLE (Enabled)
  [4] L3DAM0 — Layer 3 IP DA Match Enable
    0=DISABLE (Disabled); 1=ENABLE (Enabled)
  [3] L3SAIM0 — Layer 3 IP SA Inverse Match Enable
    0=DISABLE (Disabled); 1=ENABLE (Enabled)
  [2] L3SAM0 — Layer 3 IP SA Match Enable
    0=DISABLE (Disabled); 1=ENABLE (Enabled)
  [0] L3PEN0 — Layer 3 Protocol Enable
    0=DISABLE (Disabled); 1=ENABLE (Enabled)
0x904 MAC_Layer4_Address0
  [31:16] L4DP0 — Layer 4 Destination Port Number
  [15:0] L4SP0 — Layer 4 Source Port Number
{0x910+4i} MAC_Layer3_Addr{i}_Reg0 (i=0..3) — MAC Layer 3 Address {i} Reg 0
  [31:0] L3A{10i:02} — Layer 3 Address {i}
0x930 MAC_L3_L4_Control1
  [28] DMCHEN1 — DMA Channel Select Enable 1
    0=DISABLE (Disabled); 1=ENABLE (Enabled)
  [24] DMCHN1 — DMA Channel Number 1
  [21] L4DPIM1 — Layer 4 Destination Port Inverse Match Enable 1
    0=DISABLE (Disabled); 1=ENABLE (Enabled)
  [20] L4DPM1 — Layer 4 Destination Port Match Enable 1
    0=DISABLE (Disabled); 1=ENABLE (Enabled)
  [19] L4SPIM1 — Layer 4 Source Port Inverse Match Enable 1
    0=DISABLE (Disabled); 1=ENABLE (Enabled)
  [18] L4SPM1 — Layer 4 Source Port Match Enable 1
    0=DISABLE (Disabled); 1=ENABLE (Enabled)
  [16] L4PEN1 — Layer 4 Protocol Enable 1
    0=DISABLE (Disabled); 1=ENABLE (Enabled)
  [15:11] L3HDBM1 — Layer 3 IP DA Higher Bits Match 1
  [10:6] L3HSBM1 — Layer 3 IP SA Higher Bits Match 1
  [5] L3DAIM1 — Layer 3 IP DA Inverse Match Enable 1
    0=DISABLE (Disabled); 1=ENABLE (Enabled)
  [4] L3DAM1 — Layer 3 IP DA Match Enable 1
    0=DISABLE (Disabled); 1=ENABLE (Enabled)
  [3] L3SAIM1 — Layer 3 IP SA Inverse Match Enable 1
    0=DISABLE (Disabled); 1=ENABLE (Enabled)
  [2] L3SAM1 — Layer 3 IP SA Match Enable 1
    0=DISABLE (Disabled); 1=ENABLE (Enabled)
  [0] L3PEN1 — Layer 3 Protocol Enable 1
    0=DISABLE (Disabled); 1=ENABLE (Enabled)
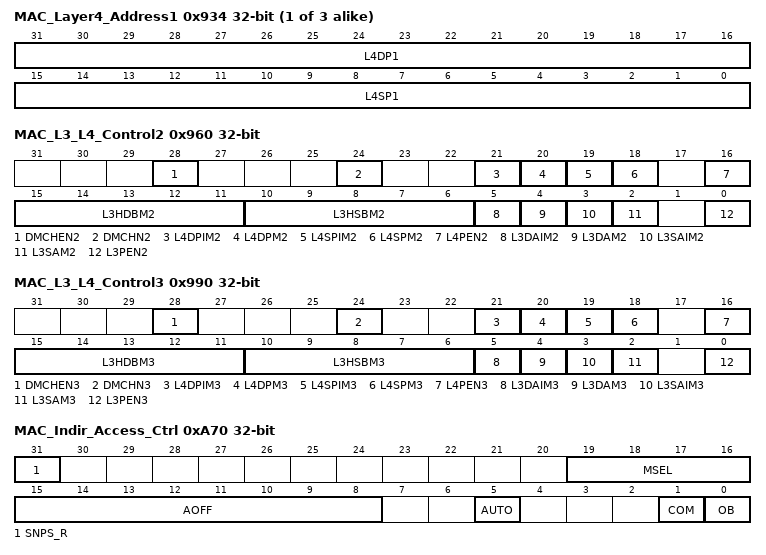
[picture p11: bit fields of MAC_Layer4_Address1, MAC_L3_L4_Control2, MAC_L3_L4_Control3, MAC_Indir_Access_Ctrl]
{0x904+0x30*i} MAC_Layer4_Address{i} (i=1..3)
  [31:16] L4DP{i} — Layer 4 Destination Port Number {i}
  [15:0] L4SP{i} — Layer 4 Source Port Number {i}
{0x940+4i} MAC_Layer3_Addr{i}_Reg1 (i=0..3) — MAC Layer 3 Address {i} Reg 1
  [31:0] L3A{10i+1:02} — Layer 3 Address {i}
0x960 MAC_L3_L4_Control2
  [28] DMCHEN2 — DMA Channel Select Enable 2
    0=DISABLE (Disabled); 1=ENABLE (Enabled)
  [24] DMCHN2 — DMA Channel Number 2
  [21] L4DPIM2 — Layer 4 Destination Port Inverse Match Enable 2
    0=DISABLE (Disabled); 1=ENABLE (Enabled)
  [20] L4DPM2 — Layer 4 Destination Port Match Enable 2
    0=DISABLE (Disabled); 1=ENABLE (Enabled)
  [19] L4SPIM2 — Layer 4 Source Port Inverse Match Enable 2
    0=DISABLE (Disabled); 1=ENABLE (Enabled)
  [18] L4SPM2 — Layer 4 Source Port Match Enable 2
    0=DISABLE (Disabled); 1=ENABLE (Enabled)
  [16] L4PEN2 — Layer 4 Protocol Enable 2
    0=DISABLE (Disabled); 1=ENABLE (Enabled)
  [15:11] L3HDBM2 — Layer 3 IP DA Higher Bits Match 2
  [10:6] L3HSBM2 — Layer 3 IP SA Higher Bits Match 2
  [5] L3DAIM2 — Layer 3 IP DA Inverse Match Enable 2
    0=DISABLE (Disabled); 1=ENABLE (Enabled)
  [4] L3DAM2 — Layer 3 IP DA Match Enable 2
    0=DISABLE (Disabled); 1=ENABLE (Enabled)
  [3] L3SAIM2 — Layer 3 IP SA Inverse Match Enable 2
    0=DISABLE (Disabled); 1=ENABLE (Enabled)
  [2] L3SAM2 — Layer 3 IP SA Match Enable 2
    0=DISABLE (Disabled); 1=ENABLE (Enabled)
  [0] L3PEN2 — Layer 3 Protocol Enable 2
    0=DISABLE (Disabled); 1=ENABLE (Enabled)
{0x970+4i} MAC_Layer3_Addr{i}_Reg2 (i=0..3) — MAC Layer 3 Address {i} Reg 2
  [31:0] L3A{10i+2:02} — Layer 3 Address {i}
0x990 MAC_L3_L4_Control3
  [28] DMCHEN3 — DMA Channel Select Enable 3
    0=DISABLE (Disabled); 1=ENABLE (Enabled)
  [24] DMCHN3 — DMA Channel Number 2
  [21] L4DPIM3 — Layer 4 Destination Port Inverse Match Enable 3
    0=DISABLE (Disabled); 1=ENABLE (Enabled)
  [20] L4DPM3 — Layer 4 Destination Port Match Enable 3
    0=DISABLE (Disabled); 1=ENABLE (Enabled)
  [19] L4SPIM3 — Layer 4 Source Port Inverse Match Enable 3
    0=DISABLE (Disabled); 1=ENABLE (Enabled)
  [18] L4SPM3 — Layer 4 Source Port Match Enable 3
    0=DISABLE (Disabled); 1=ENABLE (Enabled)
  [16] L4PEN3 — Layer 4 Protocol Enable 3
    0=DISABLE (Disabled); 1=ENABLE (Enabled)
  [15:11] L3HDBM3 — Layer 3 IP DA Higher Bits Match 3
  [10:6] L3HSBM3 — Layer 3 IP SA Higher Bits Match 3
  [5] L3DAIM3 — Layer 3 IP DA Inverse Match Enable 3
    0=DISABLE (Disabled); 1=ENABLE (Enabled)
  [4] L3DAM3 — Layer 3 IP DA Match Enable 3
    0=DISABLE (Disabled); 1=ENABLE (Enabled)
  [3] L3SAIM3 — Layer 3 IP SA Inverse Match Enable 3
    0=DISABLE (Disabled); 1=ENABLE (Enabled)
  [2] L3SAM3 — Layer 3 IP SA Match Enable 3
    0=DISABLE (Disabled); 1=ENABLE (Enabled)
  [0] L3PEN3 — Layer 3 Protocol Enable 3
    0=DISABLE (Disabled); 1=ENABLE (Enabled)
{0x9A0+4i} MAC_Layer3_Addr{i}_Reg3 (i=0..3) — MAC Layer 3 Address {i} Reg 3
  [31:0] L3A{10i+3:02} — Layer 3 Address {i}
0xA70 MAC_Indir_Access_Ctrl — MAC indirect access control register
  [31] SNPS_R — Testable: untestable
  [19:16] MSEL — Mode Select
  [15:8] AOFF — Address Offset
  [5] AUTO — Auto increment
  [1] COM — Command type
  [0] OB — Operation Busy
0xA74 MAC_Indir_Access_Data — MAC indirect access data register
  [31:0] DATA — This field contains data to read/write for Indirect address access associated with MAC_Indir_Access_Ctrl register
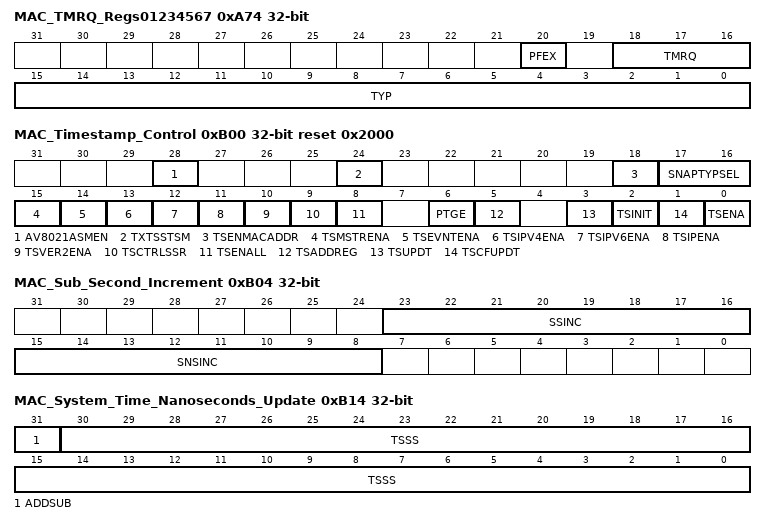
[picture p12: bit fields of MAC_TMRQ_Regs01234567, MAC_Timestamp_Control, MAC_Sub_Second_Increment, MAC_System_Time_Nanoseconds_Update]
0xA74 MAC_TMRQ_Regs01234567 (MAC_Indir_Access_Data view) — MAC type match recieve queue number register 01234567
  [20] PFEX — Preemption or Express Packet
  [18:16] TMRQ — Type Match Rx Queue Number
  [15:0] TYP — Type field Value Indicates the type value of packet that needs to be compared with received Ethernet packet
0xB00 MAC_Timestamp_Control reset 0x2000
  [28] AV8021ASMEN — AV 802.1AS Mode Enable
    0=DISABLE (Disabled); 1=ENABLE (Enabled)
  [24] TXTSSTSM — Transmit Timestamp Status Mode
    0=DISABLE (Disabled); 1=ENABLE (Enabled)
  [18] TSENMACADDR — Enable MAC Address For PTP Packet Filtering
    0=DISABLE (Disabled); 1=ENABLE (Enabled)
  [17:16] SNAPTYPSEL — Select PTP Packets For Taking Snapshots
  [15] TSMSTRENA — Enable Snapshot For Messages Relevant To Master
    0=DISABLE (Disabled); 1=ENABLE (Enabled)
  [14] TSEVNTENA — Enable Timestamp Snapshot For Event Messages
    0=DISABLE (Disabled); 1=ENABLE (Enabled)
  [13] TSIPV4ENA — Enable Processing Of PTP Packets Sent Over IPv4-UDP
    0=DISABLE (Disabled); 1=ENABLE (Enabled)
  [12] TSIPV6ENA — Enable Processing Of PTP Packets Sent Over IPv6-UDP
    0=DISABLE (Disabled); 1=ENABLE (Enabled)
  [11] TSIPENA — Enable Processing Of PTP Over Ethernet Packets
    0=DISABLE (Disabled); 1=ENABLE (Enabled)
  [10] TSVER2ENA — Enable PTP Packet Processing For Version 2 Format
    0=DISABLE (Disabled); 1=ENABLE (Enabled)
  [9] TSCTRLSSR — Timestamp Digital Or Binary Rollover Control
    0=DISABLE (Disabled); 1=ENABLE (Enabled)
  [8] TSENALL — Enable Timestamp For All Packets
    0=DISABLE (Disabled); 1=ENABLE (Enabled)
  [6] PTGE — Presentation Time Generation Enable
    0=DISABLE (Disabled); 1=ENABLE (Enabled)
  [5] TSADDREG — Update Addend Register
    0=DISABLE (Not updated); 1=ENABLE (Updated)
  [3] TSUPDT — Update Timestamp
    0=DISABLE (Not updated); 1=ENABLE (Updated)
  [2] TSINIT — Initialize Timestamp
    0=DISABLE (Not initialized); 1=ENABLE (Initialized)
  [1] TSCFUPDT — Fine Or Coarse Timestamp Update
    0=COARSE (Coarse method); 1=FINE (Fine method)
  [0] TSENA — Timestamp Enable
    0=DISABLE (Disabled); 1=ENABLE (Enabled)
0xB04 MAC_Sub_Second_Increment
  [23:16] SSINC — Sub-Second Increment Value
  [15:8] SNSINC — Sub-Nanosecond Increment Value
0xB08 MAC_System_Time_Seconds ro — MAC System Time In Seconds
  [31:0] TSS — Timestamp Second
0xB0C MAC_System_Time_Nanoseconds ro — MAC System Time In Nanoseconds
  [30:0] TSSS — Timestamp Sub Seconds
0xB10 MAC_System_Time_Seconds_Update
  [31:0] TSS — Timestamp Seconds
0xB14 MAC_System_Time_Nanoseconds_Update
  [31] ADDSUB — Add Or Subtract Time
    0=ADD (Add time); 1=SUB (Subtract time)
  [30:0] TSSS — Timestamp Subseconds
0xB18 MAC_Timestamp_Addend
  [31:0] TSAR — Timestamp Addend Register
0xB1C MAC_System_Time_Higher_Word_Seconds — MAC System Time Higher Word In Seconds
  [15:0] TSHWR — Timestamp Higher Word Register
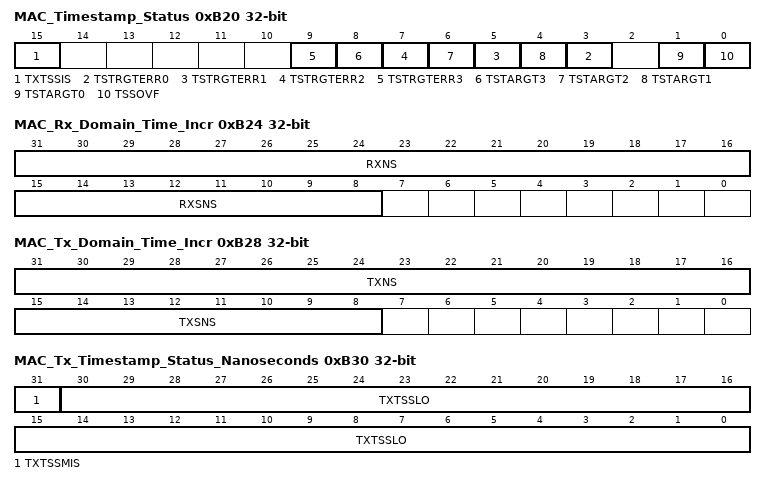
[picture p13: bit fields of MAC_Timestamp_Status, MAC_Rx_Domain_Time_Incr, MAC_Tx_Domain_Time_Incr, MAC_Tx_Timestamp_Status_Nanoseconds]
0xB20 MAC_Timestamp_Status ro
  [all] fields
    0=INACTIVE (Not detected); 1=ACTIVE (Detected)
  [15] TXTSSIS — Transmit Timestamp Status Interrupt Status
  [2n+3] TSTRGTERR{n} (n=0..3) — Timestamp Target Time Error
  [8] TSTARGT3 — Timestamp Target Time Reached For Target Time PPS3
  [6] TSTARGT2 — Timestamp Target Time Reached For Target Time PPS2
  [4] TSTARGT1 — Timestamp Target Time Reached For Target Time PPS1
  [1] TSTARGT0 — Timestamp Target Time Reached
  [0] TSSOVF — Timestamp Seconds Overflow
0xB24 MAC_Rx_Domain_Time_Incr — MAC receive clock domain time increment value register
  [31:16] RXNS — Receive Domain Time Increment Value in Nanoseconds
  [15:8] RXSNS — Receive Domain Time Increment Value in Sub-Nanoseconds
0xB28 MAC_Tx_Domain_Time_Incr — MAC transmit clock domain time increment value register
  [31:16] TXNS — transmit Domain Time Increment Value in Nanoseconds
  [15:8] TXSNS — transmit Domain Time Increment Value in Sub-Nanoseconds
0xB30 MAC_Tx_Timestamp_Status_Nanoseconds ro — MAC Transmit Timestamp Status In Nanoseconds
  [31] TXTSSMIS — Transmit Timestamp Status Missed
    0=INACTIVE (Not detected); 1=ACTIVE (Detected)
  [30:0] TXTSSLO — Transmit Timestamp Status Low
0xB34 MAC_Tx_Timestamp_Status_Seconds ro — MAC Transmit Timestamp Status In Seconds
  [31:0] TXTSSHI — Transmit Timestamp Status High
0xB50 MAC_Timestamp_Ingress_Asym_Corr — MAC Timestamp Ingress Asymmetry Correction
  [31:0] OSTIAC — One-Step Timestamp Ingress Asymmetry Correction
0xB54 MAC_Timestamp_Egress_Asym_Corr — MAC Timestamp Egress Asymmetry Correction
  [31:0] OSTEAC — One-Step Timestamp Egress Asymmetry Correction
0xB58 MAC_Timestamp_Ingress_Corr_Nanosecond — MAC Timestamp Ingress Correction In Nanoseconds
  [31:0] TSIC — Timestamp Ingress Correction
0xB5C MAC_Timestamp_Egress_Corr_Nanosecond — MAC Timestamp Egress Correction In Nanoseconds
  [31:0] TSEC — Timestamp Egress Correction
0xB60 MAC_Timestamp_Ingress_Corr_Subnanosec — MAC Timestamp Ingress Correction In Subnanoseconds
  [15:8] TSICSNS — Timestamp Ingress Correction In Sub-Nanoseconds
0xB64 MAC_Timestamp_Egress_Corr_Subnanosec — MAC Timestamp Engress Correction In Subnanoseconds
  [15:8] TSECSNS — Timestamp Egress Correction In Sub-Nanoseconds
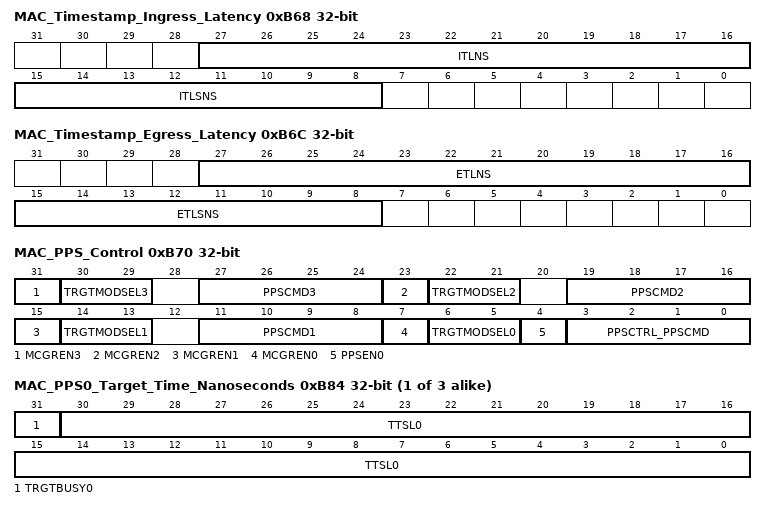
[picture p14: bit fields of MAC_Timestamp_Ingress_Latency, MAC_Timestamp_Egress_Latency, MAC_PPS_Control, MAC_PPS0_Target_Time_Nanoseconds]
0xB68 MAC_Timestamp_Ingress_Latency ro
  [27:16] ITLNS — Ingress Timestamp Latency In Sub-Nanoseconds
  [15:8] ITLSNS — Ingress Timestamp Latency In Nanoseconds
0xB6C MAC_Timestamp_Egress_Latency ro — MAC Timestamp Egress Latecy
  [27:16] ETLNS — Egress Timestamp Latency In Nanoseconds
  [15:8] ETLSNS — Egress Timestamp Latency In Sub-Nanoseconds
0xB70 MAC_PPS_Control
  [31] MCGREN3 — MCGR Mode Enable For PPS3 Output
  [30:29] TRGTMODSEL3 — Target Time Register Mode For PPS3 Output
    0=ONLY_INT (Target Time registers are programmed only for generating the interrupt event. The flexible PPS function must not be enabled in this mode, otherwise spurious transitions may be observed on the corresponding ptp_pps_o output port.); 2=INT_ST (Target Time registers are programmed for generating the interrupt event and starting or stopping the PPS0 output signal generation.); 3=ONLY_ST (Target Time registers are programmed only for starting or stopping the PPS0 output signal generation. No interrupt is asserted.)
  [27:24] PPSCMD3 — Flexible PPS3 Output Control
  [23] MCGREN2 — MCGR Mode Enable For PPS2 Output
    0=DISABLE (Disabled); 1=ENABLE (Enabled)
  [22:21] TRGTMODSEL2 — Target Time Register Mode For PPS2 Output
    values as TRGTMODSEL3
  [19:16] PPSCMD2 — Flexible PPS2 Output Control
  [15] MCGREN1 — MCGR Mode Enable For PPS1 Output
    0=DISABLE (Disabled); 1=ENABLE (Enabled)
  [14:13] TRGTMODSEL1 — Target Time Register Mode For PPS1 Output
    0=ONLY_INT (Target Time registers are programmed only for generating the interrupt event. The flexible PPS function must not be 1 in this mode, otherwise spurious transitions may be observed on the corresponding ptp_pps_o output port.); 2=INT_ST (Target Time registers are programmed for generating the interrupt event and starting or stopping the PPS0 output signal generation.); 3=ONLY_ST (Target Time registers are programmed only for starting or stopping the PPS0 output signal generation. No interrupt is asserted.)
  [11:8] PPSCMD1 — Flexible PPS1 Output Control
  [7] MCGREN0 — MCGR Mode Enable For PPS0 Output
    0=PPS (PPS mode); 1=MCGR (MCGR mode)
  [6:5] TRGTMODSEL0 — Target Time Register Mode For PPS0 Output
    values as TRGTMODSEL1
  [4] PPSEN0 — Flexible PPS Output Mode Enable 0
    0=DISABLE (Disabled); 1=ENABLE (Enabled)
  [3:0] PPSCTRL_PPSCMD — PPS Output Frequency Control
0xB80 MAC_PPS0_Target_Time_Seconds — MAC PPS0 Target Time In Seconds
  [31:0] TSTRH0 — PPS Target Time In Seconds Register
{0xB84+0x10*i} MAC_PPS{i}_Target_Time_Nanoseconds (i=0..2) — MAC PPS{i} Target Time In Nanoseconds
  [31] TRGTBUSY{i} — PPS Target Time Busy Status {i}
    0=INACTIVE (Not detected); 1=ACTIVE (Detected)
  [30:0] TTSL{i} — Target Time Low For PPS{i}
{0xB88+0x10*i} MAC_PPS{i}_Interval (i=0..2)
  [31:0] PPSINT{i} — PPS Output Signal Interval {i}
{0xB8C+0x10*i} MAC_PPS{i}_Width (i=0..3)
  [31:0] PPSWIDTH{i} — PPS Output Signal Width {i}
0xB90 MAC_PPS1_Target_Time_Seconds — MAC PPS1 Target Time In Seconds
  [31:0] TSTRH1 — PPS Target Time In Seconds 1
0xBA0 MAC_PPS2_Target_Time_Seconds — MAC PPS2 Taget Time In Seconds
  [31:0] TSTRH2 — PPS Target Time In Seconds 2
0xBB0 MAC_PPS3_Target_Time_Seconds — MAC PPS3 Target Time In Seconds
  [31:0] TSTRH3 — PPS Target Time In Seconds 3
0xBB4 MAC_PPS3_Target_Time_Nanoseconds — MAC PPS3 Target Time In Nanoseconds
  [31] TRGTBUSY3 — PPS Target Time Register Busy 3
    0=INACTIVE (Not detected); 1=ACTIVE (Detected)
  [30:0] TTSL3 — Target Time Low For PPS3
0xBB8 MAC_PPS3_Interval
  [31:0] PPSINT3 — PPS Output Signal Interval
